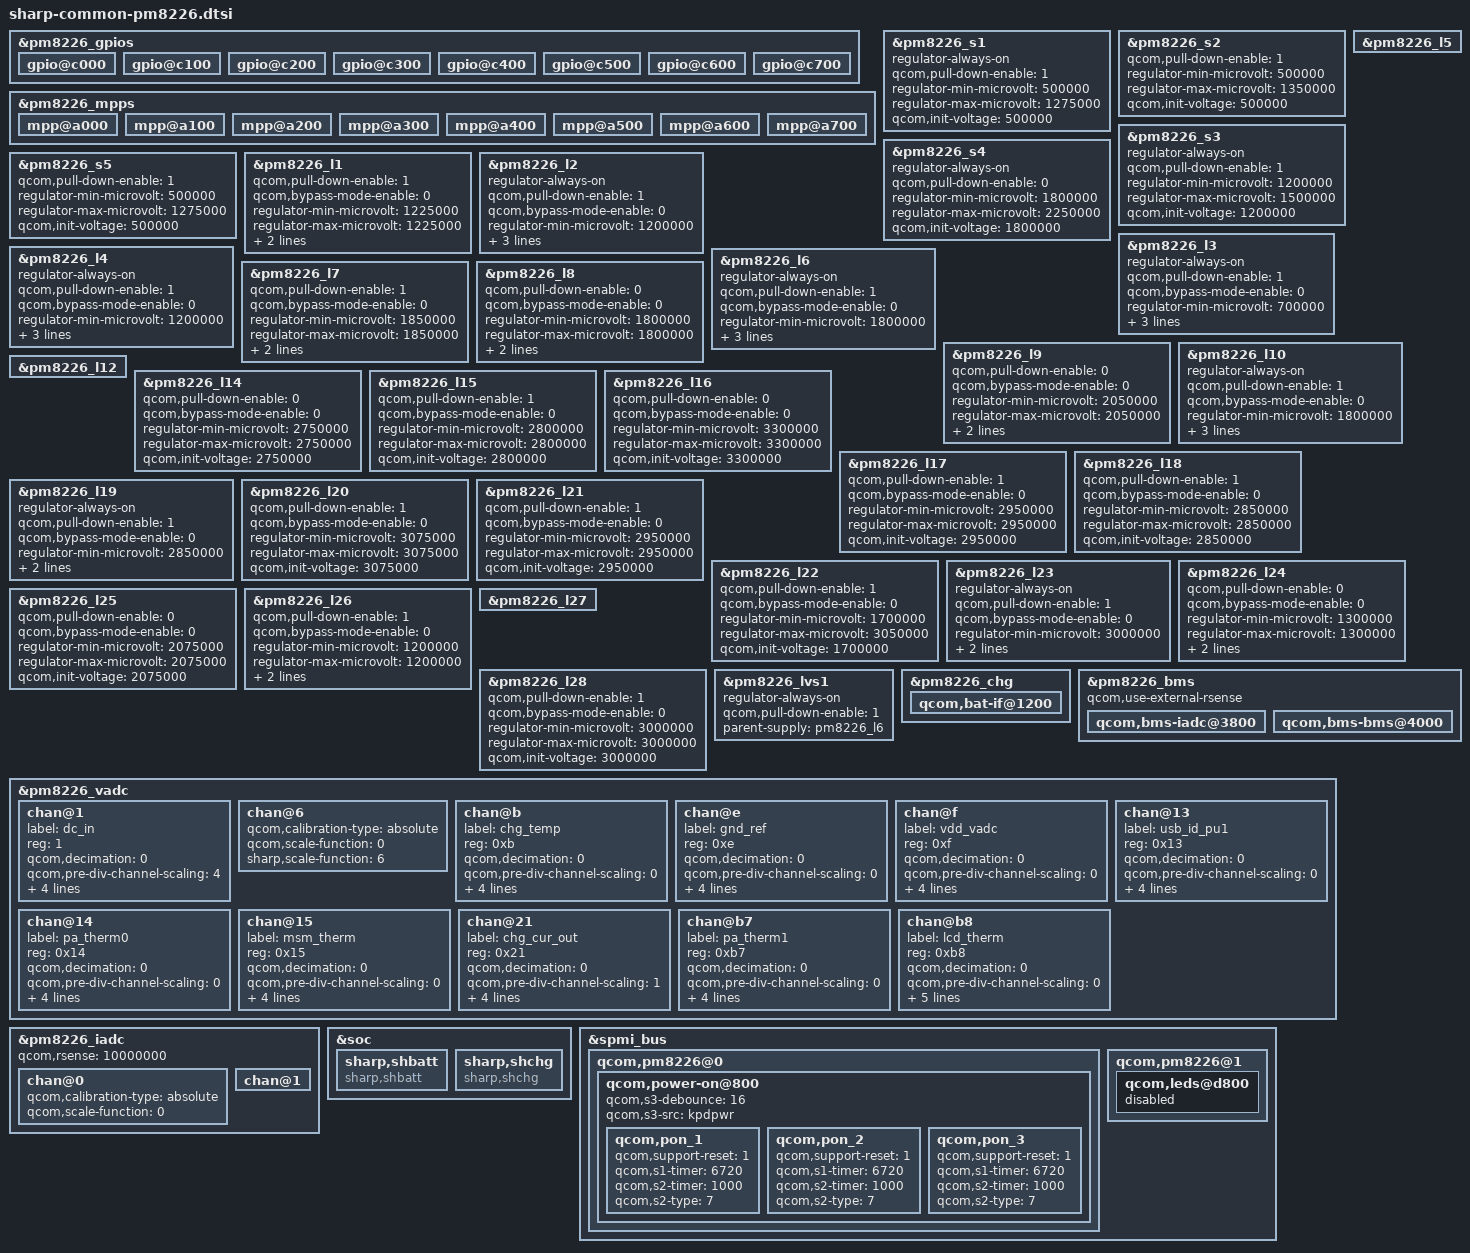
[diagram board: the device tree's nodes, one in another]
/* Copyright (c) 2013, The Linux Foundation. All rights reserved.
 *
 * This program is free software; you can redistribute it and/or modify
 * it under the terms of the GNU General Public License version 2 and
 * only version 2 as published by the Free Software Foundation.
 *
 * This program is distributed in the hope that it will be useful,
 * but WITHOUT ANY WARRANTY; without even the implied warranty of
 * MERCHANTABILITY or FITNESS FOR A PARTICULAR PURPOSE.  See the
 * GNU General Public License for more details.
 */

/*****************************************/
/*  pm8226-gpios                         */
/*****************************************/
&pm8226_gpios {
	gpio@c000 { /* GPIO 1 */
	};

	gpio@c100 { /* GPIO 2 */
	};

	gpio@c200 { /* GPIO 3 */
	};

	gpio@c300 { /* GPIO 4 */
	};

	gpio@c400 { /* GPIO 5 */
	};

	gpio@c500 { /* GPIO 6 */
	};

	gpio@c600 { /* GPIO 7 */
	};

	gpio@c700 { /* GPIO 8 */
	};
};

/*****************************************/
/*  pm8226-mpps                          */
/*****************************************/
&pm8226_mpps {
	mpp@a000 { /* MPP 1 */
	};

	mpp@a100 { /* MPP 2 */
	};

	mpp@a200 { /* MPP 3 */
	};

	mpp@a300 { /* MPP 4 */
	};

	mpp@a400 { /* MPP 5 */
	};

	mpp@a500 { /* MPP 6 */
	};

	mpp@a600 { /* MPP 7 */
	};

	mpp@a700 { /* MPP 8 */
	};
};

/*****************************************/
/*  pm8226: rpm-regulator                */
/*****************************************/
&pm8226_s1 { /* 8226_s1 */
	regulator-always-on;
	qcom,pull-down-enable = <1>;
//	qcom,auto-mode-enable = <0>;
	regulator-min-microvolt = <500000>;
	regulator-max-microvolt = <1275000>;
	qcom,init-voltage = <500000>;
	status = "okay";
};

&pm8226_s2 { /* 8226_s2 */
//	regulator-always-on;
	qcom,pull-down-enable = <1>;
//	qcom,auto-mode-enable = <0>;
	regulator-min-microvolt = <500000>;
	regulator-max-microvolt = <1350000>;
	qcom,init-voltage = <500000>;
	status = "okay";
};

&pm8226_s3 { /* 8226_s3 */
	regulator-always-on;
	qcom,pull-down-enable = <1>;
//	qcom,auto-mode-enable = <0>;
	regulator-min-microvolt = <1200000>;
	regulator-max-microvolt = <1500000>;
	qcom,init-voltage = <1200000>;
	status = "okay";
};

&pm8226_s4 { /* 8226_s4 */
	regulator-always-on;
	qcom,pull-down-enable = <0>;
//	qcom,auto-mode-enable = <0>;
	regulator-min-microvolt = <1800000>;
	regulator-max-microvolt = <2250000>;
	qcom,init-voltage = <1800000>;
	status = "okay";
};

&pm8226_s5 { /* 8226_s5 */
//	regulator-always-on;
	qcom,pull-down-enable = <1>;
//	qcom,auto-mode-enable = <0>;
	regulator-min-microvolt = <500000>;
	regulator-max-microvolt = <1275000>;
	qcom,init-voltage = <500000>;
	status = "okay";
};

&pm8226_l1 { /* 8226_l1 */
//	regulator-always-on;
	qcom,pull-down-enable = <1>;
//	qcom,auto-mode-enable = <0>;
	qcom,bypass-mode-enable = <0>;
	regulator-min-microvolt = <1225000>;
	regulator-max-microvolt = <1225000>;
	qcom,init-voltage = <1225000>;
	parent-supply = <&pm8226_s3>;
	status = "okay";
};

&pm8226_l2 { /* 8226_l2 */
	regulator-always-on;
	qcom,pull-down-enable = <1>;
//	qcom,auto-mode-enable = <0>;
	qcom,bypass-mode-enable = <0>;
	regulator-min-microvolt = <1200000>;
	regulator-max-microvolt = <1200000>;
	qcom,init-voltage = <1200000>;
	parent-supply = <&pm8226_s3>;
	status = "okay";
};

&pm8226_l3 { /* 8226_l3 */
	regulator-always-on;
	qcom,pull-down-enable = <1>;
//	qcom,auto-mode-enable = <0>;
	qcom,bypass-mode-enable = <0>;
	regulator-min-microvolt = <700000>;
	regulator-max-microvolt = <1350000>;
	qcom,init-voltage = <700000>;
	parent-supply = <&pm8226_s3>;
	status = "okay";
};

&pm8226_l4 { /* 8226_l4 */
	regulator-always-on;
	qcom,pull-down-enable = <1>;
//	qcom,auto-mode-enable = <0>;
	qcom,bypass-mode-enable = <0>;
	regulator-min-microvolt = <1200000>;
	regulator-max-microvolt = <1200000>;
	qcom,init-voltage = <1200000>;
	parent-supply = <&pm8226_s3>;
	status = "okay";
};

&pm8226_l5 { /* 8226_l5 */
//	regulator-always-on;
//	qcom,pull-down-enable = <1>;
//	qcom,auto-mode-enable = <0>;
//	qcom,bypass-mode-enable = <0>;
//	regulator-min-microvolt = <1200000>;
//	regulator-max-microvolt = <1200000>;
//	qcom,init-voltage = <1200000>;
//	parent-supply = <&pm8226_s3>;
//	status = "okay";
};

&pm8226_l6 { /* 8226_l6 */
	regulator-always-on;
	qcom,pull-down-enable = <1>;
//	qcom,auto-mode-enable = <0>;
	qcom,bypass-mode-enable = <0>;
	regulator-min-microvolt = <1800000>;
	regulator-max-microvolt = <1800000>;
	qcom,init-voltage = <1800000>;
	parent-supply = <&pm8226_s4>;
	status = "okay";
};

&pm8226_l7 { /* 8226_l7 */
//	regulator-always-on;
	qcom,pull-down-enable = <1>;
//	qcom,auto-mode-enable = <0>;
	qcom,bypass-mode-enable = <0>;
	regulator-min-microvolt = <1850000>;
	regulator-max-microvolt = <1850000>;
	qcom,init-voltage = <1850000>;
	parent-supply = <&pm8226_s4>;
	status = "okay";
};

&pm8226_l8 { /* 8226_l8 */
//	regulator-always-on;
	qcom,pull-down-enable = <0>;
//	qcom,auto-mode-enable = <0>;
	qcom,bypass-mode-enable = <0>;
	regulator-min-microvolt = <1800000>;
	regulator-max-microvolt = <1800000>;
	qcom,init-voltage = <1800000>;
	parent-supply = <&pm8226_s4>;
	status = "okay";
};

&pm8226_l9 { /* 8226_l9 */
//	regulator-always-on;
	qcom,pull-down-enable = <0>;
//	qcom,auto-mode-enable = <0>;
	qcom,bypass-mode-enable = <0>;
	regulator-min-microvolt = <2050000>;
	regulator-max-microvolt = <2050000>;
	qcom,init-voltage = <2050000>;
	parent-supply = <&pm8226_s4>;
	status = "okay";
};

&pm8226_l10 { /* 8226_l10 */
	regulator-always-on;
	qcom,pull-down-enable = <1>;
//	qcom,auto-mode-enable = <0>;
	qcom,bypass-mode-enable = <0>;
	regulator-min-microvolt = <1800000>;
	regulator-max-microvolt = <1800000>;
	qcom,init-voltage = <1800000>;
	parent-supply = <&pm8226_s4>;
	status = "okay";
};

/* 8226_l11 is not connect */

&pm8226_l12 { /* 8226_l12 */};

/* 8226_l13 is not connect */

&pm8226_l14 { /* 8226_l14 */
//	regulator-always-on;
	qcom,pull-down-enable = <0>;
//	qcom,auto-mode-enable = <0>;
	qcom,bypass-mode-enable = <0>;
	regulator-min-microvolt = <2750000>;
	regulator-max-microvolt = <2750000>;
	qcom,init-voltage = <2750000>;
	status = "okay";
};

&pm8226_l15 { /* 8226_l15 */
//	regulator-always-on;
	qcom,pull-down-enable = <1>;
//	qcom,auto-mode-enable = <0>;
	qcom,bypass-mode-enable = <0>;
	regulator-min-microvolt = <2800000>;
	regulator-max-microvolt = <2800000>;
	qcom,init-voltage = <2800000>;
	status = "okay";
};

&pm8226_l16 { /* 8226_l16 */
//	regulator-always-on;
	qcom,pull-down-enable = <0>;
//	qcom,auto-mode-enable = <0>;
	qcom,bypass-mode-enable = <0>;
	regulator-min-microvolt = <3300000>;
	regulator-max-microvolt = <3300000>;
	qcom,init-voltage = <3300000>;
	status = "okay";
};

&pm8226_l17 { /* 8226_l17 */
//	regulator-always-on;
	qcom,pull-down-enable = <1>;
//	qcom,auto-mode-enable = <0>;
	qcom,bypass-mode-enable = <0>;
	regulator-min-microvolt = <2950000>;
	regulator-max-microvolt = <2950000>;
	qcom,init-voltage = <2950000>;
	status = "okay";
};

&pm8226_l18 { /* 8226_l18 */
//	regulator-always-on;
	qcom,pull-down-enable = <1>;
//	qcom,auto-mode-enable = <0>;
	qcom,bypass-mode-enable = <0>;
	regulator-min-microvolt = <2850000>;
	regulator-max-microvolt = <2850000>;
	qcom,init-voltage = <2850000>;
	status = "okay";
};

&pm8226_l19 { /* 8226_l19 */
	regulator-always-on;
	qcom,pull-down-enable = <1>;
//	qcom,auto-mode-enable = <0>;
	qcom,bypass-mode-enable = <0>;
	regulator-min-microvolt = <2850000>;
	regulator-max-microvolt = <2850000>;
	qcom,init-voltage = <2850000>;
	status = "okay";
};

&pm8226_l20 { /* 8226_l20 */
//	regulator-always-on;
	qcom,pull-down-enable = <1>;
//	qcom,auto-mode-enable = <0>;
	qcom,bypass-mode-enable = <0>;
	regulator-min-microvolt = <3075000>;
	regulator-max-microvolt = <3075000>;
	qcom,init-voltage = <3075000>;
	status = "okay";
};

&pm8226_l21 { /* 8226_l21 */
//	regulator-always-on;
	qcom,pull-down-enable = <1>;
//	qcom,auto-mode-enable = <0>;
	qcom,bypass-mode-enable = <0>;
	regulator-min-microvolt = <2950000>;
	regulator-max-microvolt = <2950000>;
	qcom,init-voltage = <2950000>;
	status = "okay";
};

&pm8226_l22 { /* 8226_l22 */
//	regulator-always-on;
	qcom,pull-down-enable = <1>;
//	qcom,auto-mode-enable = <0>;
	qcom,bypass-mode-enable = <0>;
	regulator-min-microvolt = <1700000>;
	regulator-max-microvolt = <3050000>;
	qcom,init-voltage = <1700000>;
	status = "okay";
};

&pm8226_l23 { /* 8226_l23 */
	regulator-always-on;
	qcom,pull-down-enable = <1>;
//	qcom,auto-mode-enable = <0>;
	qcom,bypass-mode-enable = <0>;
	regulator-min-microvolt = <3000000>;
	regulator-max-microvolt = <3000000>;
	qcom,init-voltage = <3000000>;
	status = "okay";
};

&pm8226_l24 { /* 8226_l24 */
//	regulator-always-on;
	qcom,pull-down-enable = <0>;
//	qcom,auto-mode-enable = <0>;
	qcom,bypass-mode-enable = <0>;
	regulator-min-microvolt = <1300000>;
	regulator-max-microvolt = <1300000>;
	qcom,init-voltage = <1300000>;
	parent-supply = <&pm8226_s3>;
	status = "okay";
};

&pm8226_l25 { /* 8226_l25 */
//	regulator-always-on;
	qcom,pull-down-enable = <0>;
//	qcom,auto-mode-enable = <0>;
	qcom,bypass-mode-enable = <0>;
	regulator-min-microvolt = <2075000>;
	regulator-max-microvolt = <2075000>;
	qcom,init-voltage = <2075000>;
	status = "okay";
};

&pm8226_l26 { /* 8226_l26 */
//	regulator-always-on;
	qcom,pull-down-enable = <1>;
//	qcom,auto-mode-enable = <0>;
	qcom,bypass-mode-enable = <0>;
	regulator-min-microvolt = <1200000>;
	regulator-max-microvolt = <1200000>;
	qcom,init-voltage = <1200000>;
	parent-supply = <&pm8226_s3>;
	status = "okay";
};

&pm8226_l27 { /* 8226_l27 */
//	regulator-always-on;
//	qcom,pull-down-enable = <1>;
//	qcom,auto-mode-enable = <0>;
//	qcom,bypass-mode-enable = <0>;
//	regulator-min-microvolt = <1800000>;
//	regulator-max-microvolt = <1800000>;
//	qcom,init-voltage = <1800000>;
//	parent-supply = <&pm8226_s4>;
//	status = "okay";
};

&pm8226_l28 { /* 8226_l28 */
//	regulator-always-on;
	qcom,pull-down-enable = <1>;
//	qcom,auto-mode-enable = <0>;
	qcom,bypass-mode-enable = <0>;
	regulator-min-microvolt = <3000000>;
	regulator-max-microvolt = <3000000>;
	qcom,init-voltage = <3000000>;
	status = "okay";
};

&pm8226_lvs1 { /* 8226_lvs1 */
	regulator-always-on;
	qcom,pull-down-enable = <1>;
//	qcom,auto-mode-enable = <0>;
	parent-supply = <&pm8226_l6>;
	status = "okay";
};

/*****************************************/
/*  qpnp-charger                         */
/*****************************************/
&pm8226_chg {
	qcom,bat-if@1200 {
		status = "ok";
	};
};

/*****************************************/
/*  qpnp-bms                             */
/*****************************************/

&pm8226_bms {
	status = "ok";
	qcom,use-external-rsense;

	qcom,bms-iadc@3800 {
		status = "ok";
	};

	qcom,bms-bms@4000 {
		status = "ok";
	};
};

/*****************************************/
/*  qpnp-adc-voltage                     */
/*****************************************/
&pm8226_vadc {
	chan@1 { /* dc_in */
		label = "dc_in";
		reg = <1>;
		qcom,decimation = <0>;
		qcom,pre-div-channel-scaling = <4>;
		qcom,calibration-type = "absolute";
		qcom,scale-function = <0>;
		qcom,hw-settle-time = <0>;
		qcom,fast-avg-setup = <0>;
	};

	chan@6 { /* vbat_sns */
//		qcom,decimation = <0>;
//		qcom,pre-div-channel-scaling = <1>;
		qcom,calibration-type = "absolute";
		qcom,scale-function = <0>;
//		qcom,hw-settle-time = <0>;
//		qcom,fast-avg-setup = <0>;
		sharp,scale-function = <6>;
	};

	chan@b { /* chg_temp */
		label = "chg_temp";
		reg = <0xb>;
		qcom,decimation = <0>;
		qcom,pre-div-channel-scaling = <0>;
		qcom,calibration-type = "absolute";
		qcom,scale-function = <3>;
		qcom,hw-settle-time = <0>;
		qcom,fast-avg-setup = <0>;
	};

	chan@e { /* gnd_ref */
		label = "gnd_ref";
		reg = <0xe>;
		qcom,decimation = <0>;
		qcom,pre-div-channel-scaling = <0>;
		qcom,calibration-type = "absolute";
		qcom,scale-function = <0>;
		qcom,hw-settle-time = <0>;
		qcom,fast-avg-setup = <0>;
	};

	chan@f { /* vdd_vadc */
		label = "vdd_vadc";
		reg = <0xf>;
		qcom,decimation = <0>;
		qcom,pre-div-channel-scaling = <0>;
		qcom,calibration-type = "absolute";
		qcom,scale-function = <0>;
		qcom,hw-settle-time = <0>;
		qcom,fast-avg-setup = <0>;
	};

	chan@13 { /* mux4_1_1(mpp4) -> usb_id_pu1 */
		label = "usb_id_pu1";
		reg = <0x13>;
		qcom,decimation = <0>;
		qcom,pre-div-channel-scaling = <0>;
		qcom,calibration-type = "absolute";
		qcom,scale-function = <0>;
		qcom,hw-settle-time = <2>;
		qcom,fast-avg-setup = <0>;
	};

	chan@14 { /* mux5_1_1(mpp5) -> pa_therm0 */
		label = "pa_therm0";
		reg = <0x14>;
		qcom,decimation = <0>;
		qcom,pre-div-channel-scaling = <0>;
		qcom,calibration-type = "ratiometric";
		qcom,scale-function = <2>;
		qcom,hw-settle-time = <2>;
		qcom,fast-avg-setup = <0>;
	};

	chan@15 { /* mux6_1_1(mpp6) -> msm_therm */
		label = "msm_therm";
		reg = <0x15>;
		qcom,decimation = <0>;
		qcom,pre-div-channel-scaling = <0>;
		qcom,calibration-type = "ratiometric";
		qcom,scale-function = <2>;
		qcom,hw-settle-time = <2>;
		qcom,fast-avg-setup = <0>;
	};

	chan@21 { /* mux2_1_3(mpp2) -> chg_cur_out */
		label = "chg_cur_out";
		reg = <0x21>;
		qcom,decimation = <0>;
		qcom,pre-div-channel-scaling = <1>;
		qcom,calibration-type = "absolute";
		qcom,scale-function = <0>;
		qcom,hw-settle-time = <2>;
		qcom,fast-avg-setup = <0>;
	};

	chan@b7 { /* pa_therm1 */
		label = "pa_therm1";
		reg = <0xb7>;
		qcom,decimation = <0>;
		qcom,pre-div-channel-scaling = <0>;
		qcom,calibration-type = "ratiometric";
		qcom,scale-function = <2>;
		qcom,hw-settle-time = <2>;
		qcom,fast-avg-setup = <0>;
	};

	chan@b8 { /* quiet_therm -> lcd_therm */
		label = "lcd_therm";
		reg = <0xb8>;
		qcom,decimation = <0>;
		qcom,pre-div-channel-scaling = <0>;
		qcom,calibration-type = "absolute";
		qcom,scale-function = <0>;
		qcom,hw-settle-time = <2>;
		qcom,fast-avg-setup = <0>;
		sharp,scale-function = <4>;
	};
};

/*****************************************/
/*  qpnp-iadc                            */
/*****************************************/

&pm8226_iadc {
//	status = "ok";
	/* use external rsense */
	qcom,rsense = <10000000>;

	chan@0 { /* internal_rsense */
//		qcom,decimation = <0>;
//		qcom,pre-div-channel-scaling = <1>;
		qcom,calibration-type = "absolute";
		qcom,scale-function = <0>;
//		qcom,hw-settle-time = <0>;
//		qcom,fast-avg-setup = <0>;
	};

	chan@1 { /* external_rsense */
	};
};

/*****************************************/
/*  SHARP Device Drivers                 */
/*****************************************/

&soc {
	/*---------------------------------------*/
	/*  Battery Control Driver               */
	/*---------------------------------------*/
	sharp,shbatt {
		compatible = "sharp,shbatt";
		status = "ok";
	};

	/*---------------------------------------*/
	/*  Charger Control Driver               */
	/*---------------------------------------*/
	sharp,shchg {
		compatible = "sharp,shchg";
		status = "ok";
	};
};

&spmi_bus {
/*****************************************/
/*  qpnp-resin                           */
/*****************************************/
	qcom,pm8226@0 {
		qcom,power-on@800 {
			qcom,s3-debounce = <16>;
			qcom,s3-src = "kpdpwr";

			qcom,pon_1 {
				qcom,support-reset = <1>;
				qcom,s1-timer = <6720>;
				qcom,s2-timer = <1000>;
				qcom,s2-type = <7>;
			};

			qcom,pon_2 {
				qcom,support-reset = <1>;
				qcom,s1-timer = <6720>;
				qcom,s2-timer = <1000>;
				qcom,s2-type = <7>;
			};

			qcom,pon_3 {
				qcom,support-reset = <1>;
				qcom,s1-timer = <6720>;
				qcom,s2-timer = <1000>;
				qcom,s2-type = <7>;
			};
		};
	};

/*****************************************/
/*  Disable WLED setting                 */
/*****************************************/
    qcom,pm8226@1 {
        qcom,leds@d800 {
            status = "disabled";
        };
    };
};
